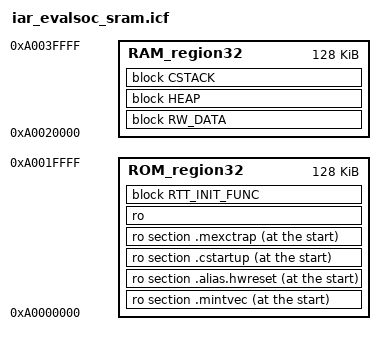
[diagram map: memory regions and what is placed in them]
//////////////////////////////////////////////////////////////////////
// RISC-V ilink configuration file
// for the Nuclei Evaluation SoC SRAM Linker File
// This is for N100 series

define exported symbol _link_file_version_2 = 1;

define memory mem with size = 4G;

/* Set memory region information according to your device */
/* For this case, ROM and RAM are both using SRAM region */
define region ROM_region32 = mem:[from 0xA0000000 size 0x20000];
define region RAM_region32 = mem:[from 0xA0020000 size 0x20000];

initialize by copy { rw };
do not initialize  { section *.noinit };
keep symbol __iar_cstart_init_gp; // defined in cstartup.s

define block CSTACK with alignment = 16, size = CSTACK_SIZE { };
define block HEAP   with alignment = 16, size = HEAP_SIZE   { };

define block RTT_INIT_FUNC with fixed order { ro section .rti_fn*, ro section FSymTab, ro section VSymTab };

define block RW_DATA with static base GPREL { rw data };
keep { ro section .alias.hwreset };
keep { section FSymTab };
keep { section VSymTab };
keep { section .rti_fn* };

"CSTARTUP32" : place at start of ROM_region32 { ro section .mintvec,
                                                ro section .alias.hwreset,
                                                ro section .cstartup,
                                                ro section .mexctrap };

"ROM32":place in ROM_region32        { ro,
                                       block RTT_INIT_FUNC,
                                    };

"RAM32":place in RAM_region32        { block RW_DATA,
                                       block HEAP,
                                       block CSTACK };
